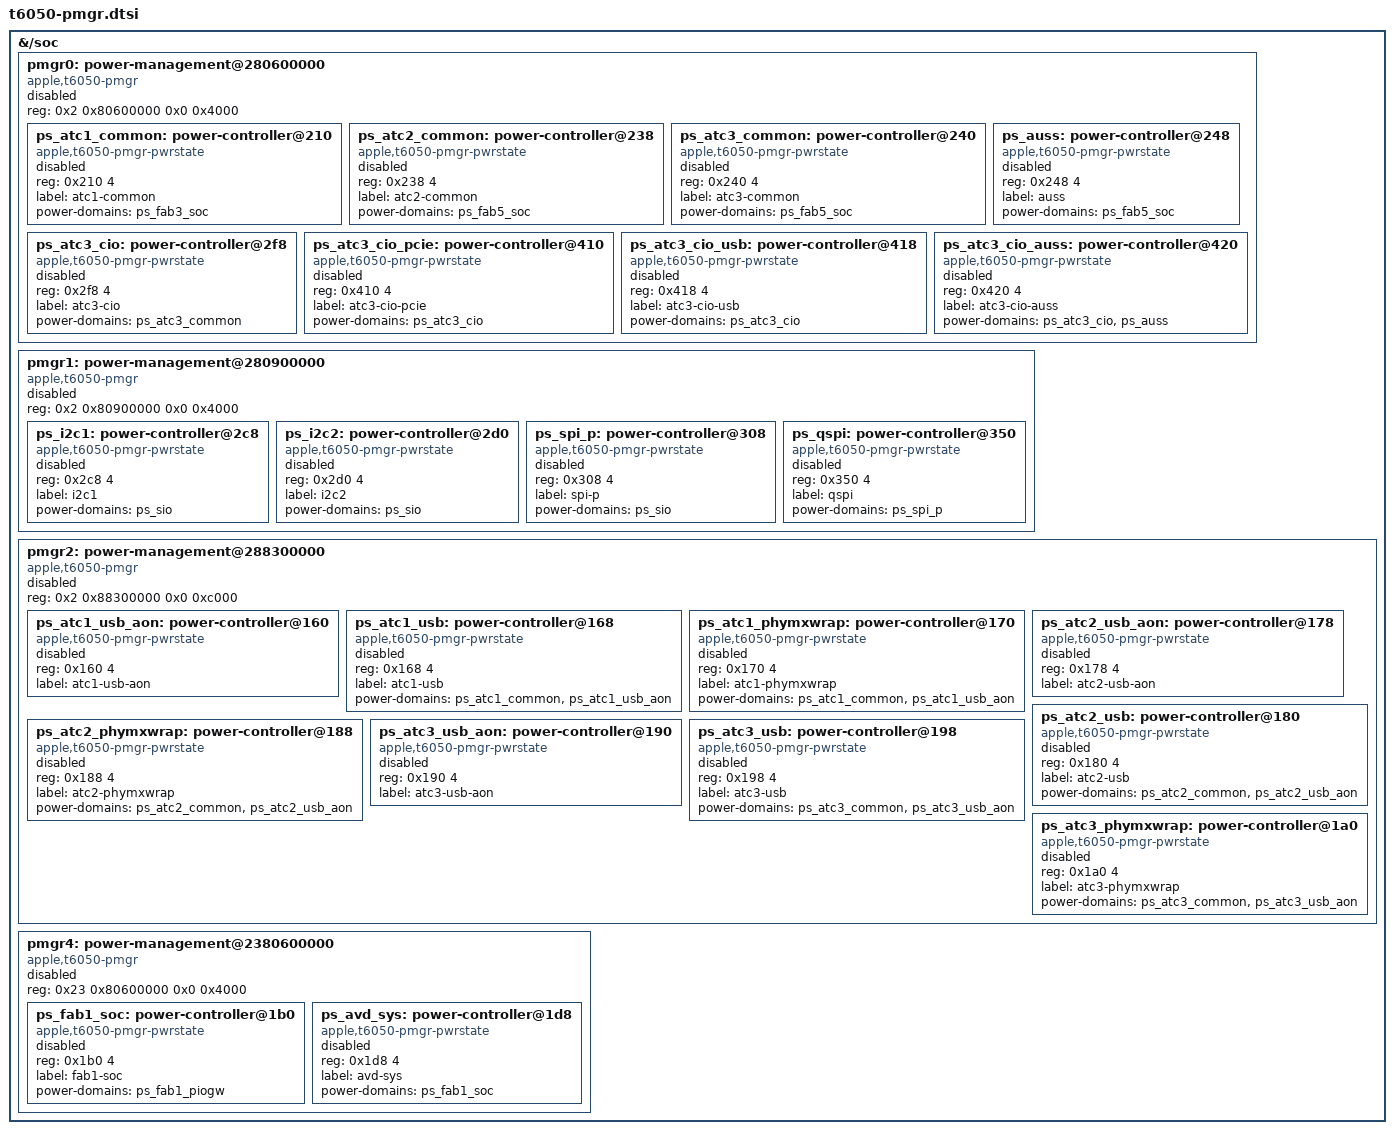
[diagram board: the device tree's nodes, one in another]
// SPDX-License-Identifier: GPL-2.0+ OR MIT
/* Native PMGR hardware graph; all providers remain disabled. */

&{/soc} {
	pmgr0: power-management@280600000 {
		compatible = "apple,t6050-pmgr", "apple,t8103-pmgr", "syscon", "simple-mfd";
		reg = <0x2 0x80600000 0x0 0x4000>;
		#address-cells = <1>;
		#size-cells = <1>;
		status = "disabled";
	};
};

&{/soc} {
	pmgr1: power-management@280900000 {
		compatible = "apple,t6050-pmgr", "apple,t8103-pmgr", "syscon", "simple-mfd";
		reg = <0x2 0x80900000 0x0 0x4000>;
		#address-cells = <1>;
		#size-cells = <1>;
		status = "disabled";
	};
};

&{/soc} {
	pmgr2: power-management@288300000 {
		compatible = "apple,t6050-pmgr", "apple,t8103-pmgr", "syscon", "simple-mfd";
		reg = <0x2 0x88300000 0x0 0xc000>;
		#address-cells = <1>;
		#size-cells = <1>;
		status = "disabled";
	};
};

&{/soc} {
	pmgr4: power-management@2380600000 {
		compatible = "apple,t6050-pmgr", "apple,t8103-pmgr", "syscon", "simple-mfd";
		reg = <0x23 0x80600000 0x0 0x4000>;
		#address-cells = <1>;
		#size-cells = <1>;
		status = "disabled";
	};
};

&pmgr0 {
	ps_atc1_common: power-controller@210 {
		compatible = "apple,t6050-pmgr-pwrstate", "apple,t8103-pmgr-pwrstate";
		reg = <0x210 4>;
		#power-domain-cells = <0>;
		#reset-cells = <0>;
		label = "atc1-common";
		power-domains = <&ps_fab3_soc>;
		status = "disabled";
	};
	ps_atc2_common: power-controller@238 {
		compatible = "apple,t6050-pmgr-pwrstate", "apple,t8103-pmgr-pwrstate";
		reg = <0x238 4>;
		#power-domain-cells = <0>;
		#reset-cells = <0>;
		label = "atc2-common";
		power-domains = <&ps_fab5_soc>;
		status = "disabled";
	};
	ps_atc3_common: power-controller@240 {
		compatible = "apple,t6050-pmgr-pwrstate", "apple,t8103-pmgr-pwrstate";
		reg = <0x240 4>;
		#power-domain-cells = <0>;
		#reset-cells = <0>;
		label = "atc3-common";
		power-domains = <&ps_fab5_soc>;
		status = "disabled";
	};
	ps_auss: power-controller@248 {
		compatible = "apple,t6050-pmgr-pwrstate", "apple,t8103-pmgr-pwrstate";
		reg = <0x248 4>;
		#power-domain-cells = <0>;
		#reset-cells = <0>;
		label = "auss";
		power-domains = <&ps_fab5_soc>;
		status = "disabled";
	};
	ps_atc3_cio: power-controller@2f8 {
		compatible = "apple,t6050-pmgr-pwrstate", "apple,t8103-pmgr-pwrstate";
		reg = <0x2f8 4>;
		#power-domain-cells = <0>;
		#reset-cells = <0>;
		label = "atc3-cio";
		power-domains = <&ps_atc3_common>;
		status = "disabled";
	};
	ps_atc3_cio_pcie: power-controller@410 {
		compatible = "apple,t6050-pmgr-pwrstate", "apple,t8103-pmgr-pwrstate";
		reg = <0x410 4>;
		#power-domain-cells = <0>;
		#reset-cells = <0>;
		label = "atc3-cio-pcie";
		power-domains = <&ps_atc3_cio>;
		status = "disabled";
	};
	ps_atc3_cio_usb: power-controller@418 {
		compatible = "apple,t6050-pmgr-pwrstate", "apple,t8103-pmgr-pwrstate";
		reg = <0x418 4>;
		#power-domain-cells = <0>;
		#reset-cells = <0>;
		label = "atc3-cio-usb";
		power-domains = <&ps_atc3_cio>;
		status = "disabled";
	};
	ps_atc3_cio_auss: power-controller@420 {
		compatible = "apple,t6050-pmgr-pwrstate", "apple,t8103-pmgr-pwrstate";
		reg = <0x420 4>;
		#power-domain-cells = <0>;
		#reset-cells = <0>;
		label = "atc3-cio-auss";
		power-domains = <&ps_atc3_cio>, <&ps_auss>;
		status = "disabled";
	};
};

&pmgr1 {
	ps_i2c1: power-controller@2c8 {
		compatible = "apple,t6050-pmgr-pwrstate", "apple,t8103-pmgr-pwrstate";
		reg = <0x2c8 4>;
		#power-domain-cells = <0>;
		#reset-cells = <0>;
		label = "i2c1";
		power-domains = <&ps_sio>;
		status = "disabled";
	};
	ps_i2c2: power-controller@2d0 {
		compatible = "apple,t6050-pmgr-pwrstate", "apple,t8103-pmgr-pwrstate";
		reg = <0x2d0 4>;
		#power-domain-cells = <0>;
		#reset-cells = <0>;
		label = "i2c2";
		power-domains = <&ps_sio>;
		status = "disabled";
	};
	ps_spi_p: power-controller@308 {
		compatible = "apple,t6050-pmgr-pwrstate", "apple,t8103-pmgr-pwrstate";
		reg = <0x308 4>;
		#power-domain-cells = <0>;
		#reset-cells = <0>;
		label = "spi-p";
		power-domains = <&ps_sio>;
		status = "disabled";
	};
	ps_qspi: power-controller@350 {
		compatible = "apple,t6050-pmgr-pwrstate", "apple,t8103-pmgr-pwrstate";
		reg = <0x350 4>;
		#power-domain-cells = <0>;
		#reset-cells = <0>;
		label = "qspi";
		power-domains = <&ps_spi_p>;
		status = "disabled";
	};
};

&pmgr2 {
	ps_atc1_usb_aon: power-controller@160 {
		compatible = "apple,t6050-pmgr-pwrstate", "apple,t8103-pmgr-pwrstate";
		reg = <0x160 4>;
		#power-domain-cells = <0>;
		#reset-cells = <0>;
		label = "atc1-usb-aon";
		status = "disabled";
	};
	ps_atc1_usb: power-controller@168 {
		compatible = "apple,t6050-pmgr-pwrstate", "apple,t8103-pmgr-pwrstate";
		reg = <0x168 4>;
		#power-domain-cells = <0>;
		#reset-cells = <0>;
		label = "atc1-usb";
		power-domains = <&ps_atc1_common>, <&ps_atc1_usb_aon>;
		status = "disabled";
	};
	ps_atc1_phymxwrap: power-controller@170 {
		compatible = "apple,t6050-pmgr-pwrstate", "apple,t8103-pmgr-pwrstate";
		reg = <0x170 4>;
		#power-domain-cells = <0>;
		#reset-cells = <0>;
		label = "atc1-phymxwrap";
		power-domains = <&ps_atc1_common>, <&ps_atc1_usb_aon>;
		status = "disabled";
	};
	ps_atc2_usb_aon: power-controller@178 {
		compatible = "apple,t6050-pmgr-pwrstate", "apple,t8103-pmgr-pwrstate";
		reg = <0x178 4>;
		#power-domain-cells = <0>;
		#reset-cells = <0>;
		label = "atc2-usb-aon";
		status = "disabled";
	};
	ps_atc2_usb: power-controller@180 {
		compatible = "apple,t6050-pmgr-pwrstate", "apple,t8103-pmgr-pwrstate";
		reg = <0x180 4>;
		#power-domain-cells = <0>;
		#reset-cells = <0>;
		label = "atc2-usb";
		power-domains = <&ps_atc2_common>, <&ps_atc2_usb_aon>;
		status = "disabled";
	};
	ps_atc2_phymxwrap: power-controller@188 {
		compatible = "apple,t6050-pmgr-pwrstate", "apple,t8103-pmgr-pwrstate";
		reg = <0x188 4>;
		#power-domain-cells = <0>;
		#reset-cells = <0>;
		label = "atc2-phymxwrap";
		power-domains = <&ps_atc2_common>, <&ps_atc2_usb_aon>;
		status = "disabled";
	};
	ps_atc3_usb_aon: power-controller@190 {
		compatible = "apple,t6050-pmgr-pwrstate", "apple,t8103-pmgr-pwrstate";
		reg = <0x190 4>;
		#power-domain-cells = <0>;
		#reset-cells = <0>;
		label = "atc3-usb-aon";
		status = "disabled";
	};
	ps_atc3_usb: power-controller@198 {
		compatible = "apple,t6050-pmgr-pwrstate", "apple,t8103-pmgr-pwrstate";
		reg = <0x198 4>;
		#power-domain-cells = <0>;
		#reset-cells = <0>;
		label = "atc3-usb";
		power-domains = <&ps_atc3_common>, <&ps_atc3_usb_aon>;
		status = "disabled";
	};
	ps_atc3_phymxwrap: power-controller@1a0 {
		compatible = "apple,t6050-pmgr-pwrstate", "apple,t8103-pmgr-pwrstate";
		reg = <0x1a0 4>;
		#power-domain-cells = <0>;
		#reset-cells = <0>;
		label = "atc3-phymxwrap";
		power-domains = <&ps_atc3_common>, <&ps_atc3_usb_aon>;
		status = "disabled";
	};
};

&pmgr4 {
	ps_fab1_soc: power-controller@1b0 {
		compatible = "apple,t6050-pmgr-pwrstate", "apple,t8103-pmgr-pwrstate";
		reg = <0x1b0 4>;
		#power-domain-cells = <0>;
		#reset-cells = <0>;
		label = "fab1-soc";
		power-domains = <&ps_fab1_piogw>;
		status = "disabled";
	};
	ps_avd_sys: power-controller@1d8 {
		compatible = "apple,t6050-pmgr-pwrstate", "apple,t8103-pmgr-pwrstate";
		reg = <0x1d8 4>;
		#power-domain-cells = <0>;
		#reset-cells = <0>;
		label = "avd-sys";
		power-domains = <&ps_fab1_soc>;
		status = "disabled";
	};
};
